# CY8C5888LTI_LP097 register map
File version: 0.1
CY8C58LP
Registers are 8-bit, read-write, no defined reset value unless marked. A register's access mark holds for its fields unless they carry their own. Offsets are from the block's base; lines under a group give offsets from that group; [hi:lo] are bit positions; {n}, {i} and the like mark numbered series; 'fields as' and 'values as' point back to an identical list; <NAME> marks a mode.

## Memory map
0x4000646B Status_ROM
0x4000646C Status_RW
0x4000646D Status_Page
0x4000647B Control_Mode
0x40006568 Status_CS

## Status_Page
Base 0x4000646D
0x00 Status_Page_STATUS_REG
0x20 Status_Page_MASK_REG
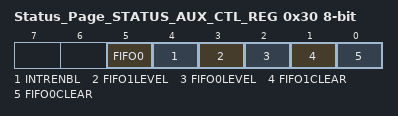
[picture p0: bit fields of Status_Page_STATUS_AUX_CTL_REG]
0x30 Status_Page_STATUS_AUX_CTL_REG
  [5] FIFO0 — FIFO0 clear
    1=ENABLED (Enable counter); 0=DISABLED (Disable counter)
  [4] INTRENBL — Enables or disables the Interrupt
    1=ENABLED (Interrupt enabled); 0=DISABLED (Interrupt disabled)
  [3] FIFO1LEVEL — FIFO level
    1=ENABLED (FIFO LVL: input mode: FIFO at least 1/2 empty; output mode: FIFO at least 1/2 full); 0=DISABLED (FIFO LVL: input mode: FIFO not full; output mode: FIFO not empty)
  [2] FIFO0LEVEL — FIFO level
    values as FIFO1LEVEL
  [1] FIFO1CLEAR — FIFO clear
    1=ENABLED (Clear FIFO state); 0=DISABLED (Normal FIFO operation)
  [0] FIFO0CLEAR — FIFO clear
    values as FIFO1CLEAR

## Status_CS
Base 0x40006568
Registers as Status_Page (with Status_Page read as Status_CS).

## Status_RW
Base 0x4000646C
Registers as Status_Page (with Status_Page read as Status_RW).

## Status_ROM
Base 0x4000646B
Registers as Status_Page (with Status_Page read as Status_ROM).

## Control_Mode
Base 0x4000647B
0x00 Control_Mode_CONTROL_REG
